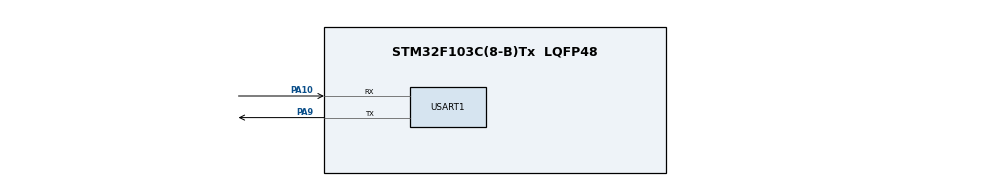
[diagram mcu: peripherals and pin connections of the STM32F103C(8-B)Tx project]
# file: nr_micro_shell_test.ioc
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FREERTOS.Tasks01=defaultTask,24,128,StartDefaultTask,Default,NULL,Dynamic,NULL,NULL;ShellTask,8,128,StartShellTask,Default,NULL,Dynamic,NULL,NULL
Mcu.Family=STM32F1
Mcu.Name=STM32F103C(8-B)Tx
Mcu.Package=LQFP48
NVIC.PriorityGroup=NVIC_PRIORITYGROUP_4
NVIC.TIM1_UP_IRQn=true\:15\:0\:false\:false\:true\:false\:false\:true\:true
NVIC.TimeBase=TIM1_UP_IRQn
NVIC.TimeBaseIP=TIM1
NVIC.USART1_IRQn=true\:5\:0\:false\:false\:true\:true\:true\:true\:true
PA10.Mode=Asynchronous
PA10.Signal=USART1_RX
PA9.Mode=Asynchronous
PA9.Signal=USART1_TX
PC14-OSC32_IN.Mode=LSE-External-Oscillator
PC14-OSC32_IN.Signal=RCC_OSC32_IN
PC15-OSC32_OUT.Mode=LSE-External-Oscillator
PC15-OSC32_OUT.Signal=RCC_OSC32_OUT
PD0-OSC_IN.Mode=HSE-External-Oscillator
PD0-OSC_IN.Signal=RCC_OSC_IN
PD1-OSC_OUT.Mode=HSE-External-Oscillator
PD1-OSC_OUT.Signal=RCC_OSC_OUT
ProjectManager.HeapSize=0x200
ProjectManager.StackSize=0x400
ProjectManager.TargetToolchain=MDK-ARM V5.32
RCC.APB1Freq_Value=8000000
RCC.APB2Freq_Value=8000000
USART1.VirtualMode=VM_ASYNC
VP_FREERTOS_VS_CMSIS_V2.Mode=CMSIS_V2
VP_SYS_VS_ND.Mode=No_Debug
VP_SYS_VS_tim1.Mode=TIM1
board=custom

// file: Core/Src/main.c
/* USER CODE BEGIN Header */
/**
  ******************************************************************************
  * @file           : main.c
  * @brief          : Main program body
  ******************************************************************************
  * @attention
  *
  * Copyright (c) 2023 STMicroelectronics.
  * All rights reserved.
  *
  * This software is licensed under terms that can be found in the LICENSE file
  * in the root directory of this software component.
  * If no LICENSE file comes with this software, it is provided AS-IS.
  *
  ******************************************************************************
  */
/* USER CODE END Header */
#include "main.h"
#include "cmsis_os2.h"
#include "usart.h"
#include "gpio.h"

/* USER CODE BEGIN Includes */
#include <elog.h>
#include <flashdb.h>
/* USER CODE END Includes */

/* USER CODE BEGIN PV */
osSemaphoreId_t sem1;
uint8_t cmd_buff[CMD_BUFF_SIZE];
/* KVDB object */
struct fdb_kvdb kvdb = { 0 };

uint32_t boot_count = 0;
time_t boot_time[10] = {0, 1, 2, 3};
/* default KV nodes */
static struct fdb_default_kv_node default_kv_table[] = {
        {"username", "armink", 0}, /* string KV */
        {"password", "123456", 0}, /* string KV */
        {"boot_count", &boot_count, sizeof(boot_count)}, /* int type KV */
        {"boot_time", &boot_time, sizeof(boot_time)},    /* int array type KV */
};
/* USER CODE END PV */

void SystemClock_Config(void);
void MX_FREERTOS_Init(void);

/* USER CODE BEGIN 0 */
void EasyLogger_Init()
{
  elog_init();
	/* set EasyLogger log format */
	elog_set_fmt(ELOG_LVL_ASSERT, ELOG_FMT_ALL);
	elog_set_fmt(ELOG_LVL_ERROR, ELOG_FMT_LVL | ELOG_FMT_TAG | ELOG_FMT_TIME);
	elog_set_fmt(ELOG_LVL_WARN, ELOG_FMT_LVL | ELOG_FMT_TAG | ELOG_FMT_TIME);
	elog_set_fmt(ELOG_LVL_INFO, ELOG_FMT_LVL | ELOG_FMT_TAG | ELOG_FMT_TIME);
	elog_set_fmt(ELOG_LVL_DEBUG, ELOG_FMT_ALL & ~(ELOG_FMT_FUNC | ELOG_FMT_T_INFO | ELOG_FMT_P_INFO));
	elog_set_fmt(ELOG_LVL_VERBOSE, ELOG_FMT_ALL & ~(ELOG_FMT_FUNC | ELOG_FMT_T_INFO | ELOG_FMT_P_INFO));
	/* start EasyLogger */
	elog_start();
}

static void lock(fdb_db_t db)
{
    __disable_irq();
}

static void unlock(fdb_db_t db)
{
    __enable_irq();
}

int FlashDB_Init()
{
  fdb_err_t result;
  /* KVDB Sample */
  struct fdb_default_kv default_kv;

  default_kv.kvs = default_kv_table;
  default_kv.num = sizeof(default_kv_table) / sizeof(default_kv_table[0]);
  /* set the lock and unlock function if you want */
  fdb_kvdb_control(&kvdb, FDB_KVDB_CTRL_SET_LOCK, (void *)lock);
  fdb_kvdb_control(&kvdb, FDB_KVDB_CTRL_SET_UNLOCK, (void *)unlock);
  /* Key-Value database initialization
    *
    *       &kvdb: database object
    *       "env": database name
    * "fdb_kvdb1": The flash partition name base on FAL. Please make sure it's in FAL partition table.
    *              Please change to YOUR partition name.
    * &default_kv: The default KV nodes. It will auto add to KVDB when first initialize successfully.
    *        NULL: The user data if you need, now is empty.
    */
  result = fdb_kvdb_init(&kvdb, "env", "fdb_kvdb1", &default_kv, NULL);

  if (result != FDB_NO_ERR) {
      return -1;
  }
	return 0;
}
/* USER CODE END 0 */

int main(void)
{

  /* MCU Configuration--------------------------------------------------------*/

  /* Reset of all peripherals, Initializes the Flash interface and the Systick. */
  HAL_Init();

  /* Configure the system clock */
  SystemClock_Config();

  /* Initialize all configured peripherals */
  MX_GPIO_Init();
  MX_USART1_UART_Init();
  /* USER CODE BEGIN 2 */
  EasyLogger_Init();
  FlashDB_Init();
  /* USER CODE END 2 */

  /* Init scheduler */
  osKernelInitialize();  /* Call init function for freertos objects (in freertos.c) */
  MX_FREERTOS_Init();

  /* Start scheduler */
  osKernelStart();

  /* We should never get here as control is now taken by the scheduler */
  /* Infinite loop */
  while (1)
  {

  }
}

void SystemClock_Config(void)
{
  RCC_OscInitTypeDef RCC_OscInitStruct = {0};
  RCC_ClkInitTypeDef RCC_ClkInitStruct = {0};

  /** Initializes the RCC Oscillators according to the specified parameters
  * in the RCC_OscInitTypeDef structure.
  */
  RCC_OscInitStruct.OscillatorType = RCC_OSCILLATORTYPE_HSI;
  RCC_OscInitStruct.HSIState = RCC_HSI_ON;
  RCC_OscInitStruct.HSICalibrationValue = RCC_HSICALIBRATION_DEFAULT;
  RCC_OscInitStruct.PLL.PLLState = RCC_PLL_NONE;
  if (HAL_RCC_OscConfig(&RCC_OscInitStruct) != HAL_OK)
  {
    Error_Handler();
  }

  /** Initializes the CPU, AHB and APB buses clocks
  */
  RCC_ClkInitStruct.ClockType = RCC_CLOCKTYPE_HCLK|RCC_CLOCKTYPE_SYSCLK
                              |RCC_CLOCKTYPE_PCLK1|RCC_CLOCKTYPE_PCLK2;
  RCC_ClkInitStruct.SYSCLKSource = RCC_SYSCLKSOURCE_HSI;
  RCC_ClkInitStruct.AHBCLKDivider = RCC_SYSCLK_DIV1;
  RCC_ClkInitStruct.APB1CLKDivider = RCC_HCLK_DIV1;
  RCC_ClkInitStruct.APB2CLKDivider = RCC_HCLK_DIV1;

  if (HAL_RCC_ClockConfig(&RCC_ClkInitStruct, FLASH_LATENCY_0) != HAL_OK)
  {
    Error_Handler();
  }
}

void HAL_TIM_PeriodElapsedCallback(TIM_HandleTypeDef *htim)
{
  if (htim->Instance == TIM1) {
    HAL_IncTick();
  }
}

void Error_Handler(void)
{
  __disable_irq();
  while (1)
  {
  }
}

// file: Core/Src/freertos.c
/* USER CODE BEGIN Header */
/**
  ******************************************************************************
  * File Name          : freertos.c
  * Description        : Code for freertos applications
  ******************************************************************************
  * @attention
  *
  * Copyright (c) 2023 STMicroelectronics.
  * All rights reserved.
  *
  * This software is licensed under terms that can be found in the LICENSE file
  * in the root directory of this software component.
  * If no LICENSE file comes with this software, it is provided AS-IS.
  *
  ******************************************************************************
  */
/* USER CODE END Header */

#include "FreeRTOS.h"
#include "task.h"
#include "main.h"
#include "cmsis_os2.h"

/* USER CODE BEGIN Includes */
#include "usart.h"
#include <stdio.h>
#include "nr_micro_shell.h"
#include <string.h>
/* USER CODE END Includes */

/* Definitions for defaultTask */
osThreadId_t defaultTaskHandle;
const osThreadAttr_t defaultTask_attributes = {
  .name = "defaultTask",
  .stack_size = 128 * 4,
  .priority = (osPriority_t) osPriorityNormal,
};
/* Definitions for ShellTask */
osThreadId_t ShellTaskHandle;
const osThreadAttr_t ShellTask_attributes = {
  .name = "ShellTask",
  .stack_size = 128 * 4,
  .priority = (osPriority_t) osPriorityLow,
};

void StartDefaultTask(void *argument);
void StartShellTask(void *argument);

void MX_FREERTOS_Init(void); /* (MISRA C 2004 rule 8.1) */

void MX_FREERTOS_Init(void) {

  /* Create the thread(s) */
  /* creation of defaultTask */
  defaultTaskHandle = osThreadNew(StartDefaultTask, NULL, &defaultTask_attributes);

  /* creation of ShellTask */
  ShellTaskHandle = osThreadNew(StartShellTask, NULL, &ShellTask_attributes);

}

void StartDefaultTask(void *argument)
{
  for(;;)
  {
    osDelay(1);
  }
}

void StartShellTask(void *argument)
{
  /* USER CODE BEGIN StartShellTask */
  /* Infinite loop */
	printf("run StartShellTask\r\n");
  sem1 = osSemaphoreNew(1, 1, NULL);
  HAL_UARTEx_ReceiveToIdle_IT(&huart1, cmd_buff, CMD_BUFF_SIZE);
  shell_init();
  for(;;)
  {
    osStatus_t ret = osSemaphoreAcquire(sem1, osWaitForever);
    if(ret == osOK) {
      int len = strlen((const char *)cmd_buff);
      for(int i=0; i<len; i++) {
        shell(cmd_buff[i]);
      }
      memset(cmd_buff, 0, CMD_BUFF_SIZE);
    }
    osDelay(1);
  }
  /* USER CODE END StartShellTask */
}
